AUTOSAR XML (schema 321)
package /ComponentType
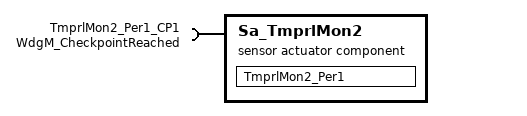
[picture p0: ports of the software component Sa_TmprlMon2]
  sensor actuator software component type Sa_TmprlMon2
    require port TmprlMon2_Per1_CP1: client-com-spec=CheckpointReached, required-interface=WdgM_CheckpointReached
  internal behavior Sa_TmprlMon2_InternalBehavior: component=Sa_TmprlMon2, port-api-option{enable-take-address=false, indirect-api=false, port=TmprlMon2_Per1_CP1}
    runnable TmprlMon2_Per1
      sync call SC_TmprlMon2_Per1_CP1_CheckpointReached: operation=TmprlMon2_Per1_CP1.CheckpointReached, timeout=0
  swc implementation Sa_TmprlMon2_Implementation: behavior=Sa_TmprlMon2_InternalBehavior
    code-descriptors:
      code Code: type=SRC
package /PortInterface
  client server interface WdgM_CheckpointReached: is-service=true
    operation CheckpointReached: possible-error=E_NOT_OK  # Indicates to the Watchdog Manager that a Checkpoint within a Supervised Entity has been reached.
    error E_NOT_OK: error-code=1
